# tviic2d6m register map
Vendor: Infineon Technologies; Series: TVIIC2D6M; File version: 1.0
CPU: CM7 r0p1, little endian, MPU, FPU, double-precision FPU, I-cache, D-cache, VTOR, ITCM, DTCM, 3 interrupt priority bits, 16 interrupts
Registers are 32-bit, read-write, reset 0x0 unless marked. A register's access mark holds for its fields unless they carry their own. Offsets are from the block's base; [hi:lo] are bit positions; lines under a group give offsets from that group; {n}, {i} and the like mark numbered series.

## FAULT — Fault structures
Base 0x40210000
{0x0+0x100*i} STRUCT[{i}] (i=0..3) group — Fault structure
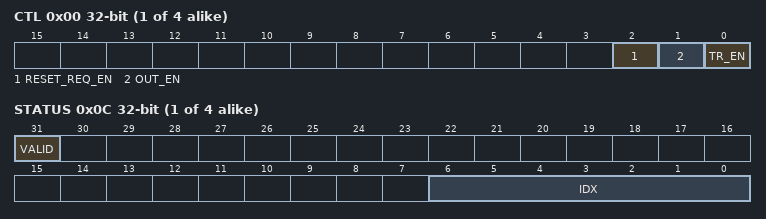
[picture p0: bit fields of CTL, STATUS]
  0x00 CTL — Fault control
    [2] RESET_REQ_EN — Reset request enable: '0': Disabled. '1': Enabled. The output reset request signal 'fault_reset_req' reflects STATUS.VALID. This reset causes a warm/soft/core reset. This warm/soft/core reset does not affect the fault logic STATUS, DATA0, ..., DATA3 registers (allowing for post soft reset failure analysis). The 'fault_reset_req' signals of the individual fault report structures are combined (logically OR'd) into a single SRSS 'fault_reset_req' signal.
    [1] OUT_EN — IO output signal enable: '0': Disabled. The IO output signal 'fault_out' is '0'. The IO output enable signal 'fault_out_en' is '0'. '1': Enabled. The IO output signal 'fault_out' reflects STATUS.VALID. The IO output enable signal 'fault_out_en' is '1'.
    [0] TR_EN — Trigger output enable: '0': Disabled. The trigger output 'tr_fault' is '0'. '1': Enabled. The trigger output 'tr_fault' reflects STATUS.VALID. The trigger can be used to initiate a Datawire transfer of the FAULT data (FAULT_DATA0 through FAULT_DATA3).
  0x0C STATUS (reset mask 0x80000000) — Fault status
    [31] VALID
    [6:0] IDX — The fault source index for which fault information is captured in DATA0 through DATA3. The fault information is fault source specific and described below. Note: this register field (and associated fault source data in DATA0 through DATA3) should only be considered valid, when VALID is '1'. The description of the encoded meaning of this field is comes from the Fault assignment in the Product TRM.
  {0x10+4j} DATA[{j}] (j=0..3) reset not defined — Fault data
    [31:0] DATA — Captured fault source data. Note: the DATA registers can only be written when STATUS.VALID is '0'. Note: the fault source index STATUS.IDX specifies the format of the DATA registers.
  0x40 PENDING0 ro reset not defined — Fault pending 0
    [31:0] SOURCE — This field specifies the following sources: Bit 0: CM0 MPU. Bit 1: CRYPTO MPU. Bit 2: DW 0 MPU. Bit 3: DW 1 MPU. Bit 4: DMA controller MPU. ... Bit 15: DAP MPU. Bit 16: CM4 system bus MPU. Bit 17: CM4 code bus MPU (for non FLASH controller accesses). Bit 18: CM4 code bus MPU (for FLASH controller accesses).
  0x44 PENDING1 ro reset not defined — Fault pending 1
    [31:0] SOURCE — This field specifies the following sources: Bit 0: Peripheral group 0 PPU. Bit 1: Peripheral group 1 PPU. Bit 2: Peripheral group 2 PPU. Bit 3: Peripheral group 3 PPU. Bit 4: Peripheral group 4 PPU. Bit 5: Peripheral group 5 PPU. Bit 6: Peripheral group 6 PPU. Bit 7: Peripheral group 7 PPU. ... Bit 15: Peripheral group 15 PPU. Bit 16 - 31: See STATUS register.
  0x48 PENDING2 ro reset not defined — Fault pending 2
    [31:0] SOURCE — This field specifies the following sources: Bit 0 - 31: See STATUS register.
  0x50 MASK0 — Fault mask 0
    [31:0] SOURCE — Fault source enables: Bits 31-0: Fault sources 31 to 0.
  0x54 MASK1 — Fault mask 1
    [31:0] SOURCE — Fault source enables: Bits 31-0: Fault sources 63 to 32.
  0x58 MASK2 — Fault mask 2
    [31:0] SOURCE — Fault source enables: Bits 31-0: Fault sources 95 to 64.
  0xC0 INTR — Interrupt
    [0] FAULT write-1-clears — This interrupt cause field is activated (HW sets the field to '1') when an enabled (MASK0/MASK1/MASK2) pending fault source is captured: - STATUS.VALID is set to '1'. - STATUS.IDX specifies the fault source index. - DATA0 through DATA3 captures the fault source data. SW writes a '1' to this field to clear the interrupt cause to '0'. SW clear STATUS.VALID to '0' to enable capture of the next fault. Note that when there is an enabled pending fault source, the pending fault source is captured immediately and INTR.FAULT is immediately activated (set to '1').
  0xC4 INTR_SET — Interrupt set
    [0] FAULT write-1-sets — SW writes a '1' to this field to set the corresponding field in the INTR register.
  0xC8 INTR_MASK — Interrupt mask
    [0] FAULT — Mask bit for corresponding field in the INTR register.
  0xCC INTR_MASKED ro — Interrupt masked
    [0] FAULT — Logical and of corresponding INTR and INTR_MASK fields.

## CANFD0 (part 1 of 3) — CAN Controller
Base 0x40520000
Same registers: CANFD1 0x40540000
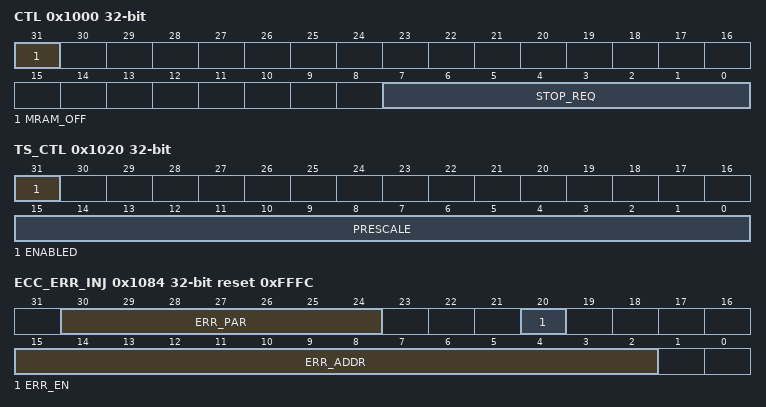
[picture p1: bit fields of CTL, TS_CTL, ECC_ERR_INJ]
0x1000 CTL — Global CAN control register
  [31] MRAM_OFF — MRAM off 0= Default MRAM on (with MRAM retained in DeepSleep). 1= Switch MRAM off (not retained) to save power. Before setting this bit all the CAN channels have to be powered down using the STOP_REQ/ACK bits. When the MRAM is off any access attempt to it is considered an address error (as if MRAM_SIZE=0). After switching the MRAM on again software needs to allow for a certain power up time before MRAM can be used, i.e. before STOP_REQ can be de-asserted. The power up time is equivalent to the system SRAM power up time specified in the CPUSS.RAM_PWR_DELAY_CTL register. MRAM_OFF should be set to 0 prior to transitioning to Hibernate mode.
  [7:0] STOP_REQ
0x1004 STATUS ro — Global CAN status register
  [7:0] STOP_ACK — Clock Stop Acknowledge for each TTCAN IP. These bits are directly driven by m_ttcan_clkstop_ack of each TTCAN IP. When this bit is set the corresponding TTCAN IP clocks will be gated off, except HCLK will enabled for each AHB write
0x1010 INTR0_CAUSE ro — Consolidated interrupt0 cause register
  [7:0] INT0 — Show pending m_ttcan_int0 of each channel
0x1014 INTR1_CAUSE ro — Consolidated interrupt1 cause register
  [7:0] INT1 — Show pending m_ttcan_int1 of each channel
0x1020 TS_CTL — Time Stamp control register
  [31] ENABLED — Counter enable bit 0 = Count disabled. Stop counting up and keep the counter value 1 = Count enabled. Start counting up from the current value
  [15:0] PRESCALE — Time Stamp counter prescale value. When enabled divide the Host clock (HCLK) by PRESCALE+1 to create Time Stamp clock ticks.
0x1024 TS_CNT — Time Stamp counter value
  [15:0] VALUE — The counter value of the Time Stamp Counter. When enabled this counter will count Time Stamp clock ticks from the pre-scaler. When written this counter and the pre-scaler will reset to 0 (write data is ignored).
0x1080 ECC_CTL — ECC control
  [16] ECC_EN — Enable ECC for CANFD SRAM When disabled also all error injection functionality is disabled.
0x1084 ECC_ERR_INJ reset 0xFFFC — ECC error injection
  [30:24] ERR_PAR — ECC Parity bits to use for ECC error injection at address ERR_ADDR.
  [20] ERR_EN — Enable error injection (ECC_EN must be 1). When this bit is set the error parity (ERR_PAR) will be used when an AHB write is done to the ERR_ADDR address. When the error word is read a single or double error will be reported to the fault structure just like for a real ECC error (even if this bit is no longer set). When this bit is set (and ECC_EN=1) a non-correctable error (ECC or address error) for the ERR_ADDR will not be reported back to the CAN channel or AHB bus.
  [15:2] ERR_ADDR — Specifies the address of the word where an error will be injected on write or an non-correctable error will be suppressed. When the ERR_EN bit is set an error parity (ERR_PAR) is injected when any write, from bus or a CAN channel, is done to this address. When the ERR_EN bit is set and the access address matches ERR_ADDR then a non-correctable ECC error or an Address error will NOT result in a bus error or CAN channel shutdown. Note that error reporting to the fault structure cannot be suppressed.
